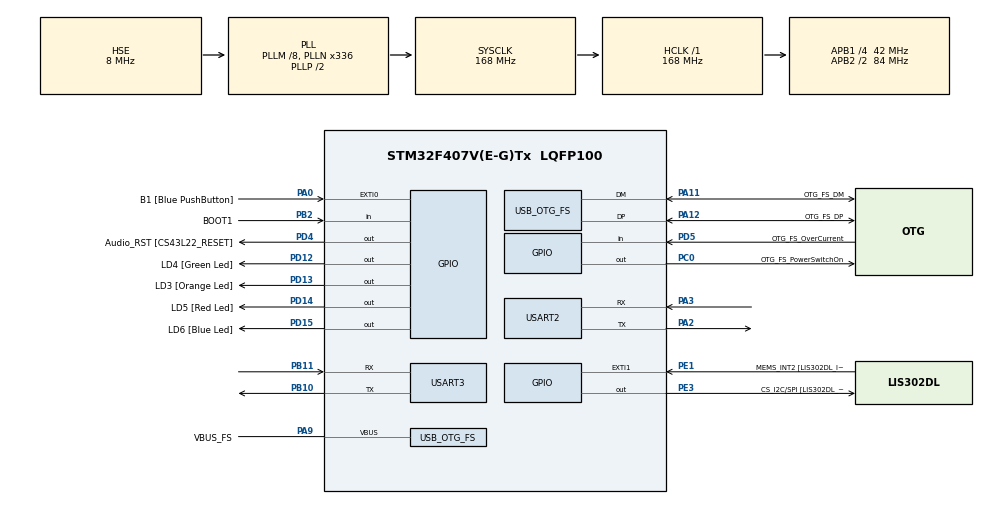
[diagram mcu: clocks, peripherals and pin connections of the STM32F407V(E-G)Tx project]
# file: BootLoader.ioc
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Mcu.Family=STM32F4
Mcu.Name=STM32F407V(E-G)Tx
Mcu.Package=LQFP100
NVIC.OTG_FS_IRQn=true\:0\:0\:false\:false\:true\:true\:true
NVIC.PriorityGroup=NVIC_PRIORITYGROUP_0
NVIC.USART2_IRQn=true\:0\:0\:false\:false\:true\:true\:true
NVIC.USART3_IRQn=true\:0\:0\:false\:false\:true\:true\:true
PA0-WKUP.GPIO_Label=B1 [Blue PushButton]
PA0-WKUP.GPIO_ModeDefaultEXTI=GPIO_MODE_EVT_RISING
PA0-WKUP.GPIO_PuPd=GPIO_NOPULL
PA0-WKUP.Signal=GPXTI0
PA10.GPIO_Label=OTG_FS_ID
PA10.GPIO_Mode=GPIO_MODE_AF_PP
PA10.GPIO_PuPd=GPIO_NOPULL
PA10.GPIO_Speed=GPIO_SPEED_FREQ_LOW
PA10.Signal=USB_OTG_FS_ID
PA11.GPIO_Label=OTG_FS_DM
PA11.GPIO_Mode=GPIO_MODE_AF_PP
PA11.GPIO_PuPd=GPIO_NOPULL
PA11.GPIO_Speed=GPIO_SPEED_FREQ_LOW
PA11.Mode=Host_Only
PA11.Signal=USB_OTG_FS_DM
PA12.GPIO_Label=OTG_FS_DP
PA12.GPIO_Mode=GPIO_MODE_AF_PP
PA12.GPIO_PuPd=GPIO_NOPULL
PA12.GPIO_Speed=GPIO_SPEED_FREQ_LOW
PA12.Mode=Host_Only
PA12.Signal=USB_OTG_FS_DP
PA13.GPIO_Label=SWDIO
PA13.Mode=Serial_Wire
PA13.Signal=SYS_JTMS-SWDIO
PA14.GPIO_Label=SWCLK
PA14.Mode=Serial_Wire
PA14.Signal=SYS_JTCK-SWCLK
PA2.Mode=Asynchronous
PA2.Signal=USART2_TX
PA3.Mode=Asynchronous
PA3.Signal=USART2_RX
PA9.GPIO_Label=VBUS_FS
PA9.GPIO_Mode=GPIO_MODE_INPUT
PA9.GPIO_PuPd=GPIO_NOPULL
PA9.Mode=Activate_VBUS
PA9.Signal=USB_OTG_FS_VBUS
PB10.Mode=Asynchronous
PB10.Signal=USART3_TX
PB11.Mode=Asynchronous
PB11.Signal=USART3_RX
PB2.GPIO_Label=BOOT1
PB2.GPIO_Mode=GPIO_MODE_INPUT
PB2.GPIO_PuPd=GPIO_NOPULL
PB2.Signal=GPIO_Input
PB3.GPIO_Label=SWO
PB3.Signal=SYS_JTDO-SWO
PC0.GPIO_Label=OTG_FS_PowerSwitchOn
PC0.GPIO_PuPd=GPIO_NOPULL
PC0.GPIO_Speed=GPIO_SPEED_FREQ_LOW
PC0.PinState=GPIO_PIN_SET
PC0.Signal=GPIO_Output
PC14-OSC32_IN.GPIO_Label=PC14-OSC32_IN
PC14-OSC32_IN.Mode=LSE-External-Oscillator
PC14-OSC32_IN.Signal=RCC_OSC32_IN
PC15-OSC32_OUT.GPIO_Label=PC15-OSC32_OUT
PC15-OSC32_OUT.Mode=LSE-External-Oscillator
PC15-OSC32_OUT.Signal=RCC_OSC32_OUT
PD12.GPIO_Label=LD4 [Green Led]
PD12.GPIO_PuPd=GPIO_NOPULL
PD12.GPIO_Speed=GPIO_SPEED_FREQ_LOW
PD12.Signal=GPIO_Output
PD13.GPIO_Label=LD3 [Orange Led]
PD13.GPIO_PuPd=GPIO_NOPULL
PD13.GPIO_Speed=GPIO_SPEED_FREQ_LOW
PD13.Signal=GPIO_Output
PD14.GPIO_Label=LD5 [Red Led]
PD14.GPIO_PuPd=GPIO_NOPULL
PD14.GPIO_Speed=GPIO_SPEED_FREQ_LOW
PD14.Signal=GPIO_Output
PD15.GPIO_Label=LD6 [Blue Led]
PD15.GPIO_PuPd=GPIO_NOPULL
PD15.GPIO_Speed=GPIO_SPEED_FREQ_LOW
PD15.Signal=GPIO_Output
PD4.GPIO_Label=Audio_RST [CS43L22_RESET]
PD4.GPIO_PuPd=GPIO_NOPULL
PD4.GPIO_Speed=GPIO_SPEED_FREQ_LOW
PD4.Signal=GPIO_Output
PD5.GPIO_Label=OTG_FS_OverCurrent
PD5.GPIO_Mode=GPIO_MODE_INPUT
PD5.GPIO_PuPd=GPIO_NOPULL
PD5.Signal=GPIO_Input
PE1.GPIO_Label=MEMS_INT2 [LIS302DL_INT2]
PE1.GPIO_ModeDefaultEXTI=GPIO_MODE_EVT_RISING
PE1.GPIO_PuPd=GPIO_NOPULL
PE1.Signal=GPXTI1
PE3.GPIO_Label=CS_I2C/SPI [LIS302DL_CS_I2C/SPI]
PE3.GPIO_PuPd=GPIO_NOPULL
PE3.GPIO_Speed=GPIO_SPEED_FREQ_LOW
PE3.Signal=GPIO_Output
PH0-OSC_IN.GPIO_Label=PH0-OSC_IN
PH0-OSC_IN.Mode=HSE-External-Oscillator
PH0-OSC_IN.Signal=RCC_OSC_IN
PH1-OSC_OUT.GPIO_Label=PH1-OSC_OUT
PH1-OSC_OUT.Mode=HSE-External-Oscillator
PH1-OSC_OUT.Signal=RCC_OSC_OUT
ProjectManager.HeapSize=0x200
ProjectManager.StackSize=0x400
ProjectManager.TargetToolchain=Makefile
RCC.48MHZClocksFreq_Value=48000000
RCC.AHBFreq_Value=168000000
RCC.APB1CLKDivider=RCC_HCLK_DIV4
RCC.APB1Freq_Value=42000000
RCC.APB1TimFreq_Value=84000000
RCC.APB2CLKDivider=RCC_HCLK_DIV2
RCC.APB2Freq_Value=84000000
RCC.APB2TimFreq_Value=168000000
RCC.CortexFreq_Value=168000000
RCC.HCLKFreq_Value=168000000
RCC.HSE_VALUE=8000000
RCC.HSI_VALUE=16000000
RCC.PLLM=8
RCC.PLLN=336
RCC.PLLQ=7
RCC.SYSCLKFreq_VALUE=168000000
RCC.SYSCLKSource=RCC_SYSCLKSOURCE_PLLCLK
RCC.VCOOutputFreq_Value=336000000
USART2.VirtualMode=VM_ASYNC
USART3.VirtualMode=VM_ASYNC
USB_HOST.BSP.number=1
USB_HOST.USBH_HandleTypeDef-CDC_FS=hUsbHostFS
USB_HOST.VirtualModeFS=Cdc
USB_HOST0.BSP.STBoard=false
USB_HOST0.BSP.api=Unknown
USB_HOST0.BSP.i2caddr=0
USB_HOST0.BSP.i2creg=0
USB_HOST0.BSP.instance=PC0
USB_HOST0.BSP.ip=GPIO
USB_HOST0.BSP.mode=Output
USB_HOST0.BSP.name=Drive_VBUS_FS
USB_HOST0.BSP.solution=PC0
USB_OTG_FS.VirtualMode=Host_Only
USB_OTG_FS.phy_itface=HCD_PHY_EMBEDDED
VP_USB_HOST_VS_USB_HOST_CDC_FS.Mode=CDC_FS
board=STM32F407G-DISC1

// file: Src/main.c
/* USER CODE BEGIN Header */
/**
  ******************************************************************************
  * @file           : main.c
  * @brief          : Main program body
  ******************************************************************************
  * @attention
  *
  * <h2><center>&copy; Copyright (c) 2020 STMicroelectronics.
  * All rights reserved.</center></h2>
  *
  * This software component is licensed by ST under Ultimate Liberty license
  * SLA0044, the "License"; You may not use this file except in compliance with
  * the License. You may obtain a copy of the License at:
  *                             www.st.com/SLA0044
  *
  ******************************************************************************
  */
/* USER CODE END Header */

#include "main.h"
#include "usb_host.h"

/* USER CODE BEGIN Includes */
#include "xmodem.h"
#include "flash.h"
/* USER CODE END Includes */

UART_HandleTypeDef huart2;
UART_HandleTypeDef huart3;

/* USER CODE BEGIN PV */
uint16_t LEDS[4] = {LD3_Pin, LD4_Pin, LD5_Pin, LD6_Pin};
/* USER CODE END PV */

void SystemClock_Config(void);
static void MX_GPIO_Init(void);
static void MX_USART2_UART_Init(void);
static void MX_USART3_UART_Init(void);
void MX_USB_HOST_Process(void);

int main(void)
{

  /* MCU Configuration--------------------------------------------------------*/

  /* Reset of all peripherals, Initializes the Flash interface and the Systick. */
  HAL_Init();

  /* USER CODE BEGIN Init */
  MX_GPIO_Init();

  /* USER CODE END Init */

  /* Configure the system clock */
  SystemClock_Config();
  if(!HAL_GPIO_ReadPin(GPIOA, GPIO_PIN_0))
  {
    uart_transmit_str((uint8_t*)"\rJumping to user application...\n\r");
    flash_jump_to_app();
  }

  /* Initialize all configured peripherals */

  // MX_USB_HOST_Init();
  MX_USART2_UART_Init();
  MX_USART3_UART_Init();
  /* USER CODE BEGIN 2 */
  uart_transmit_str((uint8_t*)"\r================================\n");
  uart_transmit_str((uint8_t*)"\rUART Bootloader\n");
  uart_transmit_str((uint8_t*)"\r================================\n\n");

  /* USER CODE END 2 */

  /* Infinite loop */
  while (1)
  {
    /* USER CODE BEGIN 3 */
    HAL_GPIO_WritePin(GPIOD, LD3_Pin, GPIO_PIN_SET);
    /* Ask for new data and start the Xmodem protocol. */
    uart_transmit_str((uint8_t*)"\rPlease send a new binary file with Xmodem protocol to update the firmware.\n");
    xmodem_receive();
    /* We only exit the xmodem protocol, if there are any errors.
     * In that case, notify the user and start over. */
    uart_transmit_str((uint8_t*)"\r\nFailed... Please try again.\n");
  }
  /* USER CODE END 3 */
}

void SystemClock_Config(void)
{
  RCC_OscInitTypeDef RCC_OscInitStruct = {0};
  RCC_ClkInitTypeDef RCC_ClkInitStruct = {0};

  /** Configure the main internal regulator output voltage
  */
  __HAL_RCC_PWR_CLK_ENABLE();
  __HAL_PWR_VOLTAGESCALING_CONFIG(PWR_REGULATOR_VOLTAGE_SCALE1);
  /** Initializes the CPU, AHB and APB busses clocks
  */
  RCC_OscInitStruct.OscillatorType = RCC_OSCILLATORTYPE_HSE;
  RCC_OscInitStruct.HSEState = RCC_HSE_ON;
  RCC_OscInitStruct.PLL.PLLState = RCC_PLL_ON;
  RCC_OscInitStruct.PLL.PLLSource = RCC_PLLSOURCE_HSE;
  RCC_OscInitStruct.PLL.PLLM = 8;
  RCC_OscInitStruct.PLL.PLLN = 336;
  RCC_OscInitStruct.PLL.PLLP = RCC_PLLP_DIV2;
  RCC_OscInitStruct.PLL.PLLQ = 7;
  if (HAL_RCC_OscConfig(&RCC_OscInitStruct) != HAL_OK)
  {
    Error_Handler();
  }
  /** Initializes the CPU, AHB and APB busses clocks
  */
  RCC_ClkInitStruct.ClockType = RCC_CLOCKTYPE_HCLK|RCC_CLOCKTYPE_SYSCLK
                              |RCC_CLOCKTYPE_PCLK1|RCC_CLOCKTYPE_PCLK2;
  RCC_ClkInitStruct.SYSCLKSource = RCC_SYSCLKSOURCE_PLLCLK;
  RCC_ClkInitStruct.AHBCLKDivider = RCC_SYSCLK_DIV1;
  RCC_ClkInitStruct.APB1CLKDivider = RCC_HCLK_DIV4;
  RCC_ClkInitStruct.APB2CLKDivider = RCC_HCLK_DIV2;

  if (HAL_RCC_ClockConfig(&RCC_ClkInitStruct, FLASH_LATENCY_5) != HAL_OK)
  {
    Error_Handler();
  }
}

static void MX_USART2_UART_Init(void)
{

  huart2.Instance = USART2;
  huart2.Init.BaudRate = 115200;
  huart2.Init.WordLength = UART_WORDLENGTH_8B;
  huart2.Init.StopBits = UART_STOPBITS_1;
  huart2.Init.Parity = UART_PARITY_NONE;
  huart2.Init.Mode = UART_MODE_TX_RX;
  huart2.Init.HwFlowCtl = UART_HWCONTROL_NONE;
  huart2.Init.OverSampling = UART_OVERSAMPLING_16;
  if (HAL_UART_Init(&huart2) != HAL_OK)
  {
    Error_Handler();
  }

}

static void MX_USART3_UART_Init(void)
{

  huart3.Instance = USART3;
  huart3.Init.BaudRate = 115200;
  huart3.Init.WordLength = UART_WORDLENGTH_8B;
  huart3.Init.StopBits = UART_STOPBITS_1;
  huart3.Init.Parity = UART_PARITY_NONE;
  huart3.Init.Mode = UART_MODE_TX_RX;
  huart3.Init.HwFlowCtl = UART_HWCONTROL_NONE;
  huart3.Init.OverSampling = UART_OVERSAMPLING_16;
  if (HAL_UART_Init(&huart3) != HAL_OK)
  {
    Error_Handler();
  }

}

static void MX_GPIO_Init(void)
{
  GPIO_InitTypeDef GPIO_InitStruct = {0};

  /* GPIO Ports Clock Enable */
  __HAL_RCC_GPIOE_CLK_ENABLE();
  __HAL_RCC_GPIOC_CLK_ENABLE();
  __HAL_RCC_GPIOH_CLK_ENABLE();
  __HAL_RCC_GPIOA_CLK_ENABLE();
  __HAL_RCC_GPIOB_CLK_ENABLE();
  __HAL_RCC_GPIOD_CLK_ENABLE();

  /*Configure GPIO pin Output Level */
  HAL_GPIO_WritePin(CS_I2C_SPI_GPIO_Port, CS_I2C_SPI_Pin, GPIO_PIN_RESET);

  /*Configure GPIO pin Output Level */
  HAL_GPIO_WritePin(OTG_FS_PowerSwitchOn_GPIO_Port, OTG_FS_PowerSwitchOn_Pin, GPIO_PIN_SET);

  /*Configure GPIO pin Output Level */
  HAL_GPIO_WritePin(GPIOD, LD4_Pin|LD3_Pin|LD5_Pin|LD6_Pin
                          |Audio_RST_Pin, GPIO_PIN_RESET);

  /*Configure GPIO pin : CS_I2C_SPI_Pin */
  GPIO_InitStruct.Pin = CS_I2C_SPI_Pin;
  GPIO_InitStruct.Mode = GPIO_MODE_OUTPUT_PP;
  GPIO_InitStruct.Pull = GPIO_NOPULL;
  GPIO_InitStruct.Speed = GPIO_SPEED_FREQ_LOW;
  HAL_GPIO_Init(CS_I2C_SPI_GPIO_Port, &GPIO_InitStruct);

  /*Configure GPIO pin : OTG_FS_PowerSwitchOn_Pin */
  GPIO_InitStruct.Pin = OTG_FS_PowerSwitchOn_Pin;
  GPIO_InitStruct.Mode = GPIO_MODE_OUTPUT_PP;
  GPIO_InitStruct.Pull = GPIO_NOPULL;
  GPIO_InitStruct.Speed = GPIO_SPEED_FREQ_LOW;
  HAL_GPIO_Init(OTG_FS_PowerSwitchOn_GPIO_Port, &GPIO_InitStruct);

  /*Configure GPIO pin : B1_Pin */
  GPIO_InitStruct.Pin = B1_Pin;
  GPIO_InitStruct.Mode = GPIO_MODE_EVT_RISING;
  GPIO_InitStruct.Pull = GPIO_NOPULL;
  HAL_GPIO_Init(B1_GPIO_Port, &GPIO_InitStruct);

  /*Configure GPIO pin : BOOT1_Pin */
  GPIO_InitStruct.Pin = BOOT1_Pin;
  GPIO_InitStruct.Mode = GPIO_MODE_INPUT;
  GPIO_InitStruct.Pull = GPIO_NOPULL;
  HAL_GPIO_Init(BOOT1_GPIO_Port, &GPIO_InitStruct);

  /*Configure GPIO pins : LD4_Pin LD3_Pin LD5_Pin LD6_Pin
                           Audio_RST_Pin */
  GPIO_InitStruct.Pin = LD4_Pin|LD3_Pin|LD5_Pin|LD6_Pin
                          |Audio_RST_Pin;
  GPIO_InitStruct.Mode = GPIO_MODE_OUTPUT_PP;
  GPIO_InitStruct.Pull = GPIO_NOPULL;
  GPIO_InitStruct.Speed = GPIO_SPEED_FREQ_LOW;
  HAL_GPIO_Init(GPIOD, &GPIO_InitStruct);

  /*Configure GPIO pin : OTG_FS_OverCurrent_Pin */
  GPIO_InitStruct.Pin = OTG_FS_OverCurrent_Pin;
  GPIO_InitStruct.Mode = GPIO_MODE_INPUT;
  GPIO_InitStruct.Pull = GPIO_NOPULL;
  HAL_GPIO_Init(OTG_FS_OverCurrent_GPIO_Port, &GPIO_InitStruct);

  /*Configure GPIO pin : MEMS_INT2_Pin */
  GPIO_InitStruct.Pin = MEMS_INT2_Pin;
  GPIO_InitStruct.Mode = GPIO_MODE_EVT_RISING;
  GPIO_InitStruct.Pull = GPIO_NOPULL;
  HAL_GPIO_Init(MEMS_INT2_GPIO_Port, &GPIO_InitStruct);

  GPIO_InitStruct.Pin = GPIO_PIN_0;
  GPIO_InitStruct.Mode = GPIO_MODE_INPUT;
  GPIO_InitStruct.Pull = GPIO_NOPULL;
  HAL_GPIO_Init(GPIOA, &GPIO_InitStruct);

}

void Error_Handler(void)
{
  while(1) {
  }
}

/************************ (C) COPYRIGHT STMicroelectronics *****END OF FILE****/
